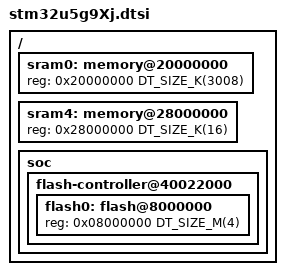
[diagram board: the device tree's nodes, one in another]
/*
 * Copyright (c) 2025 Charles Dias
 *
 * SPDX-License-Identifier: Apache-2.0
 */

#include <mem.h>
#include <st/u5/stm32u5g9.dtsi>

/ {
	sram0: memory@20000000 {
		/* SRAM1 + SRAM2 + SRAM3 + SRAM5 + SRAM6 */
		/* 768K + 64K + 832K + 832K + 512 */
		reg = <0x20000000 DT_SIZE_K(3008)>;
	};

	sram4: memory@28000000 {
		/* SRAM4, low-power background autonomous mode */
		reg = <0x28000000 DT_SIZE_K(16)>;
	};

	soc {
		flash-controller@40022000 {
			flash0: flash@8000000 {
				reg = <0x08000000 DT_SIZE_M(4)>;
			};
		};
	};
};
